# CY8C3246LTI_149 register map
File version: 0.1
CY8C32
Registers are 8-bit, read-write, no defined reset value unless marked. A register's access mark holds for its fields unless they carry their own. Offsets are from the block's base; lines under a group give offsets from that group; [hi:lo] are bit positions; {n}, {i} and the like mark numbered series; 'fields as' and 'values as' point back to an identical list; <NAME> marks a mode.

## Memory map
0x00000000 pwmFan
0x00000000 adcVFan
0x00000000 rtcClock — RTC
0x00000000 pwmFan2
0x00000000 statusButtons

## pwmFan
Base 0x00000000
0x6527 pwmFan_COMPARE_Reg_ — UDB.D0 - Assigned Compare Value
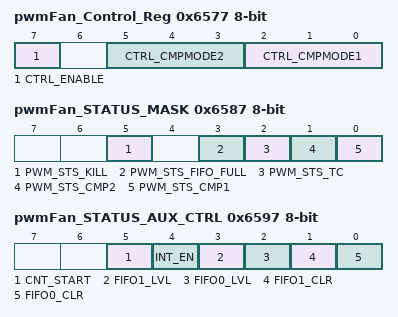
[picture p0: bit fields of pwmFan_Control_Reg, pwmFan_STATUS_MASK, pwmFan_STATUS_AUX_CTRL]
0x6577 pwmFan_Control_Reg — UDB Control Register - Assigned Control Register Value
  [7] CTRL_ENABLE — Enable the PWM
  [5:3] CTRL_CMPMODE2 — Compare mode 2
  [2:0] CTRL_CMPMODE1 — Compare mode 1
0x6587 pwmFan_STATUS_MASK — UDB Status bits Interrupt Mask Enable Register
  [5] PWM_STS_KILL ro — Enables the Interrupt on Kill
  [3] PWM_STS_FIFO_FULL ro — FIFO Full Status Mask
  [2] PWM_STS_TC ro — Enables the Interrupt on Terminal Count
  [1] PWM_STS_CMP2 ro — Enables the Interrupt on Compare 2
  [0] PWM_STS_CMP1 ro — Enables the Interrupt on Compare 1
0x6597 pwmFan_STATUS_AUX_CTRL — UDB Auxilliary Control Register
  [5] CNT_START — FIFO0 clear
    0=E_CNT_START0 (Disable counter); 1=E_CNT_START1 (Enable counter)
  [4] INT_EN
    0=E_INT_EN0 (Interrupt disabled); 1=E_INT_EN1 (Interrupt enabled)
  [3] FIFO1_LVL — FIFO level
    0=E_FIFO_LVL_0 (FIFO LVL: input mode: FIFO not full; output mode: FIFO not empty); 1=E_FIFO_LVL_1 (FIFO LVL: input mode: FIFO at least 1/2 empty; output mode: FIFO at least 1/2 full)
  [2] FIFO0_LVL — FIFO level
    values as FIFO1_LVL
  [1] FIFO1_CLR — FIFO1 clear
    0=E_FIFO_CLR_0 (Normal FIFO operation); 1=E_FIFO_CLR_1 (Clear FIFO state)
  [0] FIFO0_CLR — FIFO0 clear
    values as FIFO1_CLR

## rtcClock — RTC
Base 0x00000000
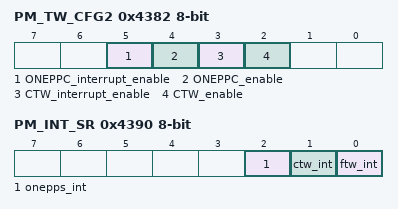
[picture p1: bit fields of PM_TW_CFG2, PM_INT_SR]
0x4382 PM_TW_CFG2 — Power timers enable and interrupt enable configuration register
  [5] ONEPPC_interrupt_enable — When set and one pulse-per-second is enabled, an interrupt is issued when the pulse occurs
    1=Enabled (The ONEPPC interrupt is issued. Only if ONEPPC is enabled.); 0=Disabled (No ONEPPC interrupt is issued.)
  [4] ONEPPC_enable
    1=Enabled (The ONEPPC is enabled.); 0=Disabled (The ONEPPC is disabled.)
  [3] CTW_interrupt_enable — An interrupt issue when the CTW reaches the selected interval
    1=Enabled (The CTW interrupt is issued. Only if CTW is enabled.); 0=Disabled (No CTW interrupt is issued.)
  [2] CTW_enable
    1=Enabled (The CTW is enabled.); 0=Disabled (The CTW is disabled.)
0x4390 PM_INT_SR — Power Manager Interrupt Status Register
  [2] onepps_int — When set, a onepps event has occured.
  [1] ctw_int — When set, a limited active ready event has occured
  [0] ftw_int — When set, a fast timewheel event has occured

## pwmFan2
Base 0x00000000
0x6526 pwmFan2_COMPARE_Reg_ — UDB.D0 - Assigned Compare Value
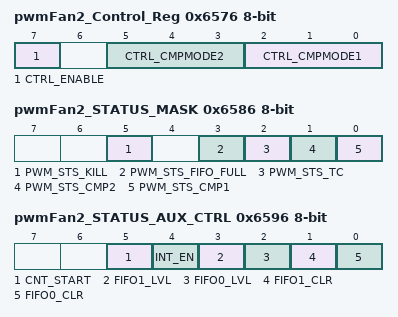
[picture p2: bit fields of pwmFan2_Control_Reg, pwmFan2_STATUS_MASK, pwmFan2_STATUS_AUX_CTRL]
0x6576 pwmFan2_Control_Reg — UDB Control Register - Assigned Control Register Value
  [7] CTRL_ENABLE — Enable the PWM
  [5:3] CTRL_CMPMODE2 — Compare mode 2
  [2:0] CTRL_CMPMODE1 — Compare mode 1
0x6586 pwmFan2_STATUS_MASK — UDB Status bits Interrupt Mask Enable Register
  [5] PWM_STS_KILL ro — Enables the Interrupt on Kill
  [3] PWM_STS_FIFO_FULL ro — FIFO Full Status Mask
  [2] PWM_STS_TC ro — Enables the Interrupt on Terminal Count
  [1] PWM_STS_CMP2 ro — Enables the Interrupt on Compare 2
  [0] PWM_STS_CMP1 ro — Enables the Interrupt on Compare 1
0x6596 pwmFan2_STATUS_AUX_CTRL — UDB Auxilliary Control Register
  [5] CNT_START — FIFO0 clear
    0=E_CNT_START0 (Disable counter); 1=E_CNT_START1 (Enable counter)
  [4] INT_EN
    0=E_INT_EN0 (Interrupt disabled); 1=E_INT_EN1 (Interrupt enabled)
  [3] FIFO1_LVL — FIFO level
    0=E_FIFO_LVL_0 (FIFO LVL: input mode: FIFO not full; output mode: FIFO not empty); 1=E_FIFO_LVL_1 (FIFO LVL: input mode: FIFO at least 1/2 empty; output mode: FIFO at least 1/2 full)
  [2] FIFO0_LVL — FIFO level
    values as FIFO1_LVL
  [1] FIFO1_CLR — FIFO1 clear
    0=E_FIFO_CLR_0 (Normal FIFO operation); 1=E_FIFO_CLR_1 (Clear FIFO state)
  [0] FIFO0_CLR — FIFO0 clear
    values as FIFO1_CLR
